# eqep register map
Vendor: Texas Instruments
Peripheral module from a debugger description file (folder am335x).
Registers are 16-bit, read-write, no defined reset value unless marked. A register's access mark holds for its fields unless they carry their own. Offsets are as the file gives them; lines under a group give offsets from that group; [hi:lo] are bit positions; {n}, {i} and the like mark numbered series; 'fields as' and 'values as' point back to an identical list; <NAME> marks a mode.

## eQEP
0x00 QPOSCNT 32-bit
  [31:0] QPOSCNT — This 32 bit position counter register counts up/down on every eQEP pulse based on direction input. This counter acts as a position integrator whose count value is proportional to position from a give reference point.
0x04 QPOSINIT 32-bit
  [31:0] QPOSINIT — This register contains the position value that is used to initialize the position counter based on external strobe or index event. The position counter can be initialized through software.
0x08 QPOSMAX 32-bit
  [31:0] QPOSMAX — This register contains the maximum position counter value.
0x0C QPOSCMP 32-bit
  [31:0] QPOSCMP — The position-compare value in this register is compared with the position counter (QPOSCNT) to generate sync output and/or interrupt on compare match.
0x10 QPOSILAT 32-bit ro
  [31:0] QPOSILAT — The position-counter value is latched into this register on an index event as defined by the QEPCTL[IEL] bits.
0x14 QPOSSLAT 32-bit ro
  [31:0] QPOSSLAT — The position-counter value is latched into this register on strobe event as defined by the QEPCTL[SEL] bits.
0x18 QPOSLAT 32-bit ro
  [31:0] QPOSLAT — The position-counter value is latched into this register on unit time out event.
0x1C QUTMR 32-bit
  [31:0] QUTMR — This register acts as time base for unit time event generation. When this timer value matches with unit time period value, unit time event is generated.
0x20 QUPRD 32-bit
  [31:0] QUPRD — This register contains the period count for unit timer to generate periodic unit time events to latch the eQEP position information at periodic interval and optionally to generate interrupt.
0x24 QWDTMR
  [15:0] QWDTMR — This register acts as time base for watch dog to detect motor stalls. When this timer value matches with watch dog period value, watch dog timeout interrupt is generated. This register is reset upon edge transition in quadrature-clock indicating the motion.
0x26 QWDPRD
  [15:0] QWDPRD — This register contains the time-out count for the eQEP peripheral watch dog timer. When the watchdog timer value matches the watchdog period value, a watchdog timeout interrupt is generated.
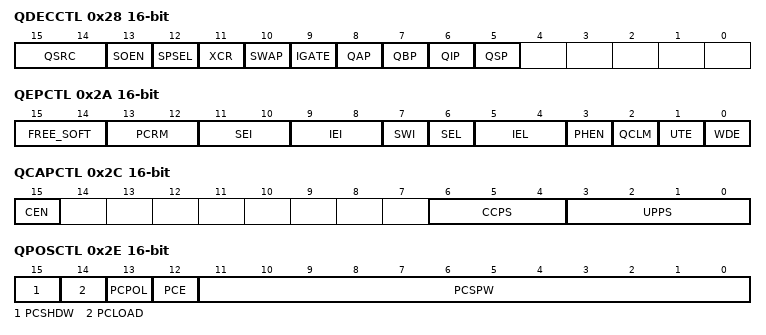
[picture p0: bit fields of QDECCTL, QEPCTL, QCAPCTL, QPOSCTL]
0x28 QDECCTL access per field
  [15:14] QSRC rw — Position-counter source selection.
  [13] SOEN rw — Sync output-enable
  [12] SPSEL rw — Sync output pin selection
  [11] XCR rw — External clock rate
  [10] SWAP rw — Swap quadrature clock inputs. This swaps the input to the quadrature decoder, reversing the counting direction.
  [9] IGATE rw — Index pulse gating option
  [8] QAP rw — QEPA input polarity
  [7] QBP rw — QEPB input polarity
  [6] QIP rw — QEPI input polarity
  [5] QSP rw — QEPS input polarity
0x2A QEPCTL
  [15:14] FREE_SOFT — Emulation Control Bits. In the values 0 through 3 listed below, x is different for the four following behaviors. QPOSCNT behavior, x refers to the Position counter. QWDTMR behavior, x refers to the Watchdog counter. QUTMR behavior, x refers to the Unit timer. QCTMR behavior, x refers to the Capture timer.
  [13:12] PCRM — Position counter reset mode
  [11:10] SEI — Strobe event initialization of position counter
  [9:8] IEI — Index event initialization of position counter
  [7] SWI — Software initialization of position counter
  [6] SEL — Strobe event latch of position counter
  [5:4] IEL — Index event latch of position counter (software index marker)
  [3] PHEN — Quadrature position counter enable/software reset
  [2] QCLM — eQEP capture latch mode
  [1] UTE — eQEP unit timer enable
  [0] WDE — eQEP watchdog enable
0x2C QCAPCTL access per field
  [15] CEN rw — Enable eQEP capture
  [6:4] CCPS rw — eQEP capture timer clock prescaler
  [3:0] UPPS rw — Unit position event prescaler
0x2E QPOSCTL
  [15] PCSHDW — Position-compare shadow enable
  [14] PCLOAD — Position-compare shadow load mode
  [13] PCPOL — Polarity of sync output
  [12] PCE — Position-compare enable/disable
  [11:0] PCSPW — Select-position-compare sync output pulse width ...
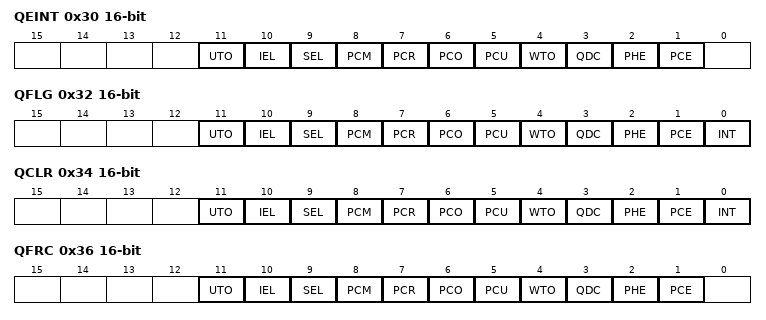
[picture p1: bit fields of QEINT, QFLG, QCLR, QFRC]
0x30 QEINT access per field
  [11] UTO rw — Unit time out interrupt enable
  [10] IEL rw — Index event latch interrupt enable
  [9] SEL rw — Strobe event latch interrupt enable
  [8] PCM rw — Position-compare match interrupt enable
  [7] PCR rw — Position-compare ready interrupt enable
  [6] PCO rw — Position counter overflow interrupt enable
  [5] PCU rw — Position counter underflow interrupt enable
  [4] WTO rw — Watchdog time out interrupt enable
  [3] QDC rw — Quadrature direction change interrupt enable
  [2] PHE rw — Quadrature phase error interrupt enable
  [1] PCE rw — Position counter error interrupt enable
0x32 QFLG ro
  [11] UTO — Unit time out interrupt flag
  [10] IEL — Index event latch interrupt flag
  [9] SEL — Strobe event latch interrupt flag
  [8] PCM — eQEP compare match event interrupt flag
  [7] PCR — Position-compare ready interrupt flag
  [6] PCO — Position counter overflow interrupt flag
  [5] PCU — Position counter underflow interrupt flag
  [4] WTO — Watchdog timeout interrupt flag
  [3] QDC — Quadrature direction change interrupt flag
  [2] PHE — Quadrature phase error interrupt flag
  [1] PCE — Position counter error interrupt flag
  [0] INT — Global interrupt status flag
0x34 QCLR access per field
  [11] UTO rw — Clear unit time out interrupt flag
  [10] IEL rw — Clear index event latch interrupt flag
  [9] SEL rw — Clear strobe event latch interrupt flag
  [8] PCM rw — Clear eQEP compare match event interrupt flag
  [7] PCR rw — Clear position-compare ready interrupt flag
  [6] PCO rw — Clear position counter overflow interrupt flag
  [5] PCU rw — Clear position counter underflow interrupt flag
  [4] WTO rw — Clear watchdog timeout interrupt flag
  [3] QDC rw — Clear quadrature direction change interrupt flag
  [2] PHE rw — Clear quadrature phase error interrupt flag
  [1] PCE rw — Clear position counter error interrupt flag
  [0] INT rw — Global interrupt clear flag
0x36 QFRC access per field
  [11] UTO rw — Force unit time out interrupt
  [10] IEL rw — Force index event latch interrupt
  [9] SEL rw — Force strobe event latch interrupt
  [8] PCM rw — Force position-compare match interrupt
  [7] PCR rw — Force position-compare ready interrupt
  [6] PCO rw — Force position counter overflow interrupt
  [5] PCU rw — Force position counter underflow interrupt
  [4] WTO rw — Force watchdog time out interrupt
  [3] QDC rw — Force quadrature direction change interrupt
  [2] PHE rw — Force quadrature phase error interrupt
  [1] PCE rw — Force position counter error interrupt
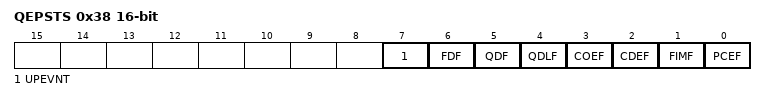
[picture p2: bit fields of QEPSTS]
0x38 QEPSTS access per field
  [7] UPEVNT ro — Unit position event flag
  [6] FDF ro — Direction on the first index marker. Status of the direction is latched on the first index event marker.
  [5] QDF ro — Quadrature direction flag
  [4] QDLF ro — eQEP direction latch flag. Status of direction is latched on every index event marker.
  [3] COEF rw — Capture overflow error flag
  [2] CDEF rw — Capture direction error flag
  [1] FIMF rw — First index marker flag
  [0] PCEF ro — Position counter error flag. This bit is not sticky and it is updated for every index event.
0x3A QCTMR
  [15:0] QCTMR — This register provides time base for edge capture unit.
0x3C QCPRD
  [15:0] QCPRD — This register holds the period count value between the last successive eQEP position events
0x3E QCTMRLAT ro
  [15:0] QCTMRLAT — The eQEP capture timer value can be latched into this register on two events, that is, unit timeout event, reading the eQEP position counter.
0x40 QCPRDLAT
  [15:0] QCPRDLAT — eQEP capture period value can be latched into this register on two events, that is, unit timeout event, reading the eQEP position counter.
0x5C REVID 32-bit ro
  [31:0] REV — eQEP revision ID
